# R7FA4M3AF register map
Vendor: Renesas Electronics Corporation; Series: RA4; File version: 1.40.00
CPU: CM33 r0p4, little endian, MPU, FPU, VTOR, 4 interrupt priority bits, 96 interrupts
Registers are 8-bit, read-write, reset 0x0 unless marked. A register's access mark holds for its fields unless they carry their own. Offsets are from the block's base; [hi:lo] are bit positions; {n}, {i} and the like mark numbered series.

## CTSU — Capacitive Touch Sensing Unit
Base 0x400D0000
0x00 CTSUCR0 — CTSU Control Register 0
0x01 CTSUCR1 — CTSU Control Register 1
0x02 CTSUSDPRS — CTSU Synchronous Noise Reduction Setting Register
0x03 CTSUSST — CTSU Sensor Stabilization Wait Control Register
0x04 CTSUMCH0 reset 0x1F — CTSU Measurement Channel Register 0
0x05 CTSUMCH1 ro reset 0x1F — CTSU Measurement Channel Register 1
{0x6+i} CTSUCHAC{i} (i=0..2) — CTSU Channel Enable Control Register {i}
{0xB+i} CTSUCHTRC{i} (i=0..2) — CTSU Channel Transmit/Receive Control Register {i}
0x10 CTSUDCLKC — CTSU High,Pass Noise Reduction Control Register
0x11 CTSUST — CTSU Status Register
0x12 CTSUSSC 16-bit — CTSU High,Pass Noise Reduction Spectrum Diffusion Control Register
  [11:8] CTSUSSDIV — CTSU Spectrum Diffusion Frequency Division Setting
0x14 CTSUSO0 16-bit — CTSU Sensor Offset Register 0
0x16 CTSUSO1 16-bit — CTSU Sensor Offset Register 1
0x18 CTSUSC 16-bit ro — CTSU Sensor Counter
0x1A CTSURC 16-bit ro — CTSU Reference Counter
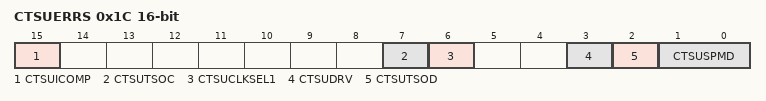
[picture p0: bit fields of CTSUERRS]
0x1C CTSUERRS 16-bit (reset mask 0x7FFF) — CTSU Error Status Register
  [15] CTSUICOMP ro — TSCAP Voltage Error Monitor
  [7] CTSUTSOC — Calibration Setting 2
  [6] CTSUCLKSEL1 — Calibration Setting 3
  [3] CTSUDRV — Calibration Setting 1
  [2] CTSUTSOD — TS Pin Fixed Output
  [1:0] CTSUSPMD — Calibration Mode
0x20 CTSUTRMR reset not defined — CTSU Reference Current Calibration Register

## AGT0 — Low Power Asynchronous General Purpose Timer 0
Base 0x400E8000
Same registers: AGT1 0x400E8100, AGT2 0x400E8200, AGT3 0x400E8300, AGT4 0x400E8400, AGT5 0x400E8500
0x00 AGT 16-bit reset 0xFFFF — AGT Counter Register
0x02 AGTCMA 16-bit reset 0xFFFF — AGT Compare Match A Register
0x04 AGTCMB 16-bit reset 0xFFFF — AGT Compare Match B Register
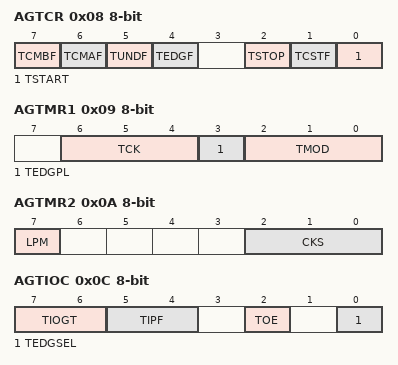
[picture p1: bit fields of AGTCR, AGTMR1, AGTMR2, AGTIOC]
0x08 AGTCR — AGT Control Register
  [7] TCMBF — Compare Match B Flag
  [6] TCMAF — Compare Match A Flag
  [5] TUNDF — Underflow Flag
  [4] TEDGF — Active Edge Judgment Flag
  [2] TSTOP wo — AGT Count Forced Stop
  [1] TCSTF ro — AGT Count Status Flag
  [0] TSTART — AGT Count Start
0x09 AGTMR1 — AGT Mode Register 1
  [6:4] TCK — Count Source
  [3] TEDGPL — Edge Polarity
  [2:0] TMOD — Operating Mode
0x0A AGTMR2 — AGT Mode Register 2
  [7] LPM — Low Power Mode
  [2:0] CKS — AGTLCLK or AGTSCLK Count Source Clock Frequency Division Ratio
0x0C AGTIOC — AGT I/O Control Register
  [7:6] TIOGT — Count Control
  [5:4] TIPF — Input Filter
  [2] TOE — AGTOn pin Output Enable
  [0] TEDGSEL — I/O Polarity Switch
0x0D AGTISR — AGT Event Pin Select Register
  [2] EEPS — AGTEEn Polarity Selection
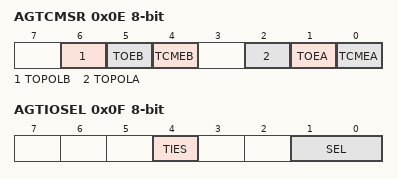
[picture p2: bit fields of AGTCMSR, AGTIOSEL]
0x0E AGTCMSR — AGT Compare Match Function Select Register
  [6] TOPOLB — AGTOBn Pin Polarity Select
  [5] TOEB — AGTOBn Pin Output Enable
  [4] TCMEB — AGT Compare Match B Register Enable
  [2] TOPOLA — AGTOAn Pin Polarity Select
  [1] TOEA — AGTOAn Pin Output Enable
  [0] TCMEA — AGT Compare Match A Register Enable
0x0F AGTIOSEL — AGT Pin Select Register
  [4] TIES — AGTIOn Pin Input Enable
  [1:0] SEL — AGTIOn Pin Select

## TSN — Temperature Sensor
Base 0x400F3000
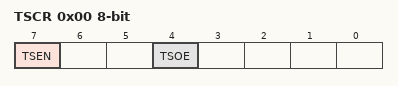
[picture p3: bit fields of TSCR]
0x00 TSCR — Temperature Sensor Control Register
  [7] TSEN — Temperature Sensor Enable
  [4] TSOE — Temperature Sensor Output Enable

## CRC — Cyclic Redundancy Check Calculator
Base 0x40108000
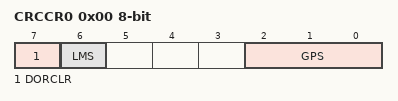
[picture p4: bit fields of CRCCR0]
0x00 CRCCR0 — CRC Control Register 0
  [7] DORCLR wo — CRCDOR/CRCDOR_HA/CRCDOR_BY Register Clear
  [6] LMS — CRC Calculation Switching
  [2:0] GPS — CRC Generating Polynomial Switching
0x04 CRCDIR 32-bit — CRC Data Input Register
0x04 CRCDIR_BY (alternate view of CRCDIR) — CRC Data Input Register
0x08 CRCDOR 32-bit — CRC Data Output Register
0x08 CRCDOR_HA 16-bit (alternate view of CRCDOR) — CRC Data Output Register
0x08 CRCDOR_BY (alternate view of CRCDOR) — CRC Data Output Register
